# ATmega2560 register map
File version: 1.0
Registers are 8-bit, read-write, reset 0x0 unless marked. A register's access mark holds for its fields unless they carry their own. Offsets are from the block's base; lines under a group give offsets from that group; [hi:lo] are bit positions; {n}, {i} and the like mark numbered series; 'fields as' and 'values as' point back to an identical list; <NAME> marks a mode.

## Memory map
0x00800000 AC — Analog Comparator
0x00800000 USART0 — USART
0x00800000 USART1 — USART
0x00800000 USART2 — USART
0x00800000 USART3 — USART
0x00800000 TWI — Two Wire Serial Interface
0x00800000 SPI — Serial Peripheral Interface
0x00800000 PORTA — I/O Port
0x00800000 PORTB — I/O Port
0x00800000 PORTC — I/O Port
0x00800000 PORTD — I/O Port
0x00800000 PORTE — I/O Port
0x00800000 PORTF — I/O Port
0x00800000 PORTG — I/O Port
0x00800000 PORTH — I/O Port
0x00800000 PORTJ — I/O Port
0x00800000 PORTK — I/O Port
0x00800000 PORTL — I/O Port
0x00800000 TC0 — Timer/Counter, 8-bit
0x00800000 TC0_2 — Timer/Counter, 8-bit
0x00800000 TC2 — Timer/Counter, 8-bit Async
0x00800000 TC2_2 — Timer/Counter, 8-bit Async
0x00800000 WDT — Watchdog Timer
0x00800000 EEPROM
0x00800000 TC5 — Timer/Counter, 16-bit
0x00800000 TC4 — Timer/Counter, 16-bit
0x00800000 TC3 — Timer/Counter, 16-bit
0x00800000 TC1 — Timer/Counter, 16-bit
0x00800000 EXINT — External Interrupts
0x00800000 EXINT_2 — External Interrupts
0x00800000 ADC — Analog-to-Digital Converter

## AC — Analog Comparator
Base 0x00800000
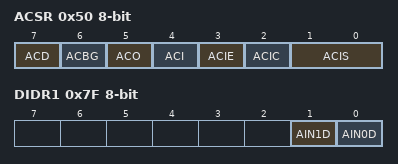
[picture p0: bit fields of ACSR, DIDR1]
0x50 ACSR — Analog Comparator Control And Status Register
  [7] ACD — Analog Comparator Disable
  [6] ACBG — Analog Comparator Bandgap Select
  [5] ACO — Analog Compare Output
  [4] ACI — Analog Comparator Interrupt Flag
  [3] ACIE — Analog Comparator Interrupt Enable
  [2] ACIC — Analog Comparator Input Capture Enable
  [1:0] ACIS — Analog Comparator Interrupt Mode Select bits
0x7B ADCSRB — ADC Control and Status Register B
  [6] ACME — Analog Comparator Multiplexer Enable
0x7F DIDR1 — Digital Input Disable Register 1
  [1] AIN1D — AIN1 Digital Input Disable
  [0] AIN0D — AIN0 Digital Input Disable

## USART0 — USART
Base 0x00800000
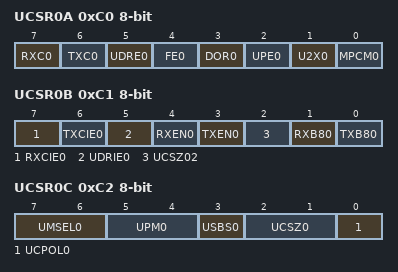
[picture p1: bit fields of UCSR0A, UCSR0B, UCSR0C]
0xC0 UCSR0A ro — USART Control and Status Register A
  [7] RXC0 — USART Receive Complete
  [6] TXC0 — USART Transmitt Complete
  [5] UDRE0 — USART Data Register Empty
  [4] FE0 — Framing Error
  [3] DOR0 — Data overRun
  [2] UPE0 — Parity Error
  [1] U2X0 — Double the USART transmission speed
  [0] MPCM0 — Multi-processor Communication Mode
0xC1 UCSR0B ro — USART Control and Status Register B
  [7] RXCIE0 — RX Complete Interrupt Enable
  [6] TXCIE0 — TX Complete Interrupt Enable
  [5] UDRIE0 — USART Data register Empty Interrupt Enable
  [4] RXEN0 — Receiver Enable
  [3] TXEN0 — Transmitter Enable
  [2] UCSZ02 — Character Size
  [1] RXB80 — Receive Data Bit 8
  [0] TXB80 — Transmit Data Bit 8
0xC2 UCSR0C ro — USART Control and Status Register C
  [7:6] UMSEL0 — USART Mode Select
  [5:4] UPM0 — Parity Mode Bits
  [3] USBS0 — Stop Bit Select
  [2:1] UCSZ0 — Character Size
  [0] UCPOL0 — Clock Polarity
0xC4 UBRR0 16-bit ro (reset mask 0xFF) — USART Baud Rate Register Bytes

## USART1 — USART
Base 0x00800000
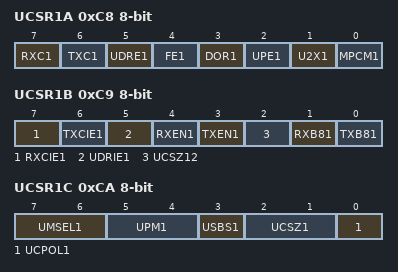
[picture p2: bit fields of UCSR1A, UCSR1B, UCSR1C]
0xC8 UCSR1A — USART Control and Status Register A
  [7] RXC1 — USART Receive Complete
  [6] TXC1 — USART Transmitt Complete
  [5] UDRE1 — USART Data Register Empty
  [4] FE1 — Framing Error
  [3] DOR1 — Data overRun
  [2] UPE1 — Parity Error
  [1] U2X1 — Double the USART transmission speed
  [0] MPCM1 — Multi-processor Communication Mode
0xC9 UCSR1B — USART Control and Status Register B
  [7] RXCIE1 — RX Complete Interrupt Enable
  [6] TXCIE1 — TX Complete Interrupt Enable
  [5] UDRIE1 — USART Data register Empty Interrupt Enable
  [4] RXEN1 — Receiver Enable
  [3] TXEN1 — Transmitter Enable
  [2] UCSZ12 — Character Size
  [1] RXB81 — Receive Data Bit 8
  [0] TXB81 — Transmit Data Bit 8
0xCA UCSR1C — USART Control and Status Register C
  [7:6] UMSEL1 — USART Mode Select
  [5:4] UPM1 — Parity Mode Bits
  [3] USBS1 — Stop Bit Select
  [2:1] UCSZ1 — Character Size
  [0] UCPOL1 — Clock Polarity
0xCC UBRR1 16-bit (reset mask 0xFF) — USART Baud Rate Register Bytes
